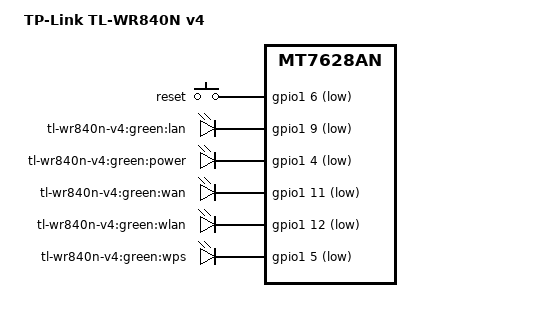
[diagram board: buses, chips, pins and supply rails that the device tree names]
/dts-v1/;

#include "TPLINK-8M.dtsi"

#include <dt-bindings/gpio/gpio.h>
#include <dt-bindings/input/input.h>

/ {
	compatible = "tplink,tl-wr840n-v4", "mediatek,mt7628an-soc";
	model = "TP-Link TL-WR840N v4";

	aliases {
		led-status = &led_power;
	};

	gpio-keys-polled {
		compatible = "gpio-keys-polled";
		poll-interval = <20>;

		reset {
			label = "reset";
			gpios = <&gpio1 6 GPIO_ACTIVE_LOW>;
			linux,code = <KEY_RESTART>;
		};
	};

	gpio-leds {
		compatible = "gpio-leds";

		lan {
			label = "tl-wr840n-v4:green:lan";
			gpios = <&gpio1 9 GPIO_ACTIVE_LOW>;
		};

		led_power: power {
			label = "tl-wr840n-v4:green:power";
			gpios = <&gpio1 4 GPIO_ACTIVE_LOW>;
		};

		wan {
			label = "tl-wr840n-v4:green:wan";
			gpios = <&gpio1 11 GPIO_ACTIVE_LOW>;
		};

		wlan {
			label = "tl-wr840n-v4:green:wlan";
			gpios = <&gpio1 12 GPIO_ACTIVE_LOW>;
		};

		wps {
			label = "tl-wr840n-v4:green:wps";
			gpios = <&gpio1 5 GPIO_ACTIVE_LOW>;
		};
	};
};

&pinctrl {
	state_default: pinctrl0 {
		gpio {
			ralink,group = "p0led_an", "p2led_an", "perst", "refclk", "wdt", "wled_an";
			ralink,function = "gpio";
		};
	};
};
